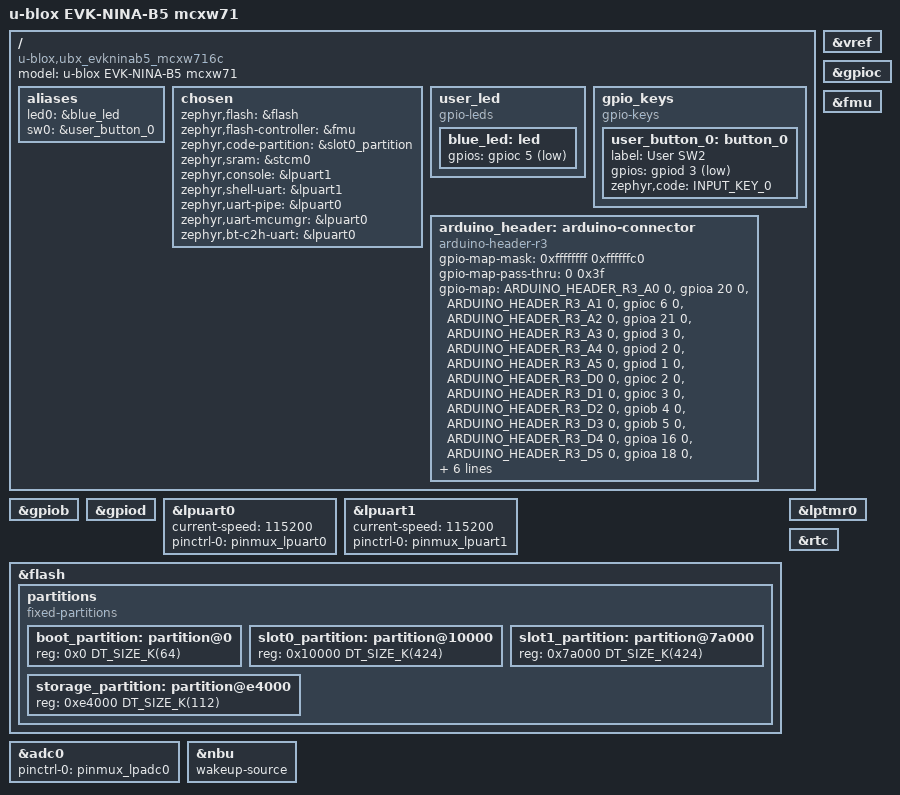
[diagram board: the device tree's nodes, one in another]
/*
 * Copyright 2026 u-blox
 * SPDX-License-Identifier: Apache-2.0
 */

/dts-v1/;

#include <nxp/mcx/nxp_mcxw71.dtsi>
#include "ubx_evkninab5_mcxw716c-pinctrl.dtsi"
#include <zephyr/dt-bindings/gpio/arduino-header-r3.h>
#include <zephyr/dt-bindings/input/input-event-codes.h>

/ {
	model = "u-blox EVK-NINA-B5 mcxw71";
	compatible = "u-blox,ubx_evkninab5_mcxw716c";

	aliases {
		led0 = &blue_led;
		sw0 = &user_button_0;
	};

	chosen {
		zephyr,flash = &flash;
		zephyr,flash-controller = &fmu;
		zephyr,code-partition = &slot0_partition;
		zephyr,sram = &stcm0;
		zephyr,console = &lpuart1;
		zephyr,shell-uart = &lpuart1;
		zephyr,uart-pipe = &lpuart0;
		zephyr,uart-mcumgr = &lpuart0;
		zephyr,bt-c2h-uart = &lpuart0;
	};

	user_led {
		compatible = "gpio-leds";

		blue_led: led {
			gpios = <&gpioc 5 GPIO_ACTIVE_LOW>;
		};
	};

	gpio_keys {
		compatible = "gpio-keys";

		user_button_0: button_0 {
			label = "User SW2";
			gpios = <&gpiod 3 (GPIO_PULL_UP | GPIO_ACTIVE_LOW)>;
			zephyr,code = <INPUT_KEY_0>;
			status = "okay";
		};
	};

	arduino_header: arduino-connector {
		compatible = "arduino-header-r3";
		#gpio-cells = <2>;
		gpio-map-mask = <0xffffffff 0xffffffc0>;
		gpio-map-pass-thru = <0 0x3f>;
		gpio-map = <ARDUINO_HEADER_R3_A0 0 &gpioa 20 0>,
			   <ARDUINO_HEADER_R3_A1 0 &gpioc 6 0>,
			   <ARDUINO_HEADER_R3_A2 0 &gpioa 21 0>,
			   <ARDUINO_HEADER_R3_A3 0 &gpiod 3 0>,
			   <ARDUINO_HEADER_R3_A4 0 &gpiod 2 0>,
			   <ARDUINO_HEADER_R3_A5 0 &gpiod 1 0>,
			   <ARDUINO_HEADER_R3_D0 0 &gpioc 2 0>,
			   <ARDUINO_HEADER_R3_D1 0 &gpioc 3 0>,
			   <ARDUINO_HEADER_R3_D2 0 &gpiob 4 0>,
			   <ARDUINO_HEADER_R3_D3 0 &gpiob 5 0>,
			   <ARDUINO_HEADER_R3_D4 0 &gpioa 16 0>,
			   <ARDUINO_HEADER_R3_D5 0 &gpioa 18 0>,
			   <ARDUINO_HEADER_R3_D9 0 &gpioa 17 0>,
			   <ARDUINO_HEADER_R3_D10 0 &gpiod 4 0>,
			   <ARDUINO_HEADER_R3_D11 0 &gpiod 5 0>,
			   <ARDUINO_HEADER_R3_D12 0 &gpioc 5 0>,
			   <ARDUINO_HEADER_R3_D14 0 &gpioc 4 0>,
			   <ARDUINO_HEADER_R3_D15 0 &gpioa 19 0>;
	};
};

&vref {
	status = "okay";
};

&gpiob {
	status = "okay";
};

&gpioc {
	status = "okay";
};

&gpiod {
	status = "okay";
};

&lpuart0 {
	current-speed = <115200>;
	status = "okay";
	pinctrl-0 = <&pinmux_lpuart0>;
	pinctrl-names = "default";
};

&lpuart1 {
	current-speed = <115200>;
	status = "okay";
	pinctrl-0 = <&pinmux_lpuart1>;
	pinctrl-names = "default";
};

&flash {
	partitions {
		compatible = "fixed-partitions";
		#address-cells = <1>;
		#size-cells = <1>;

		/*
		 * Partition sizes must be aligned
		 * to the flash memory sector size of 8KB.
		 */
		boot_partition: partition@0 {
			reg = <0x0 DT_SIZE_K(64)>;
		};

		slot0_partition: partition@10000 {
			reg = <0x10000 DT_SIZE_K(424)>;
		};

		slot1_partition: partition@7a000 {
			reg = <0x7a000 DT_SIZE_K(424)>;
		};

		storage_partition: partition@e4000 {
			reg = <0xe4000 DT_SIZE_K(112)>;
		};
	};
};

&fmu {
	status = "okay";
};

&lptmr0 {
	status = "okay";
};

&adc0 {
	pinctrl-0 = <&pinmux_lpadc0>;
	pinctrl-names = "default";
	status = "okay";
};

&nbu {
	status = "okay";
	wakeup-source;
};

&rtc {
	status = "okay";
};
